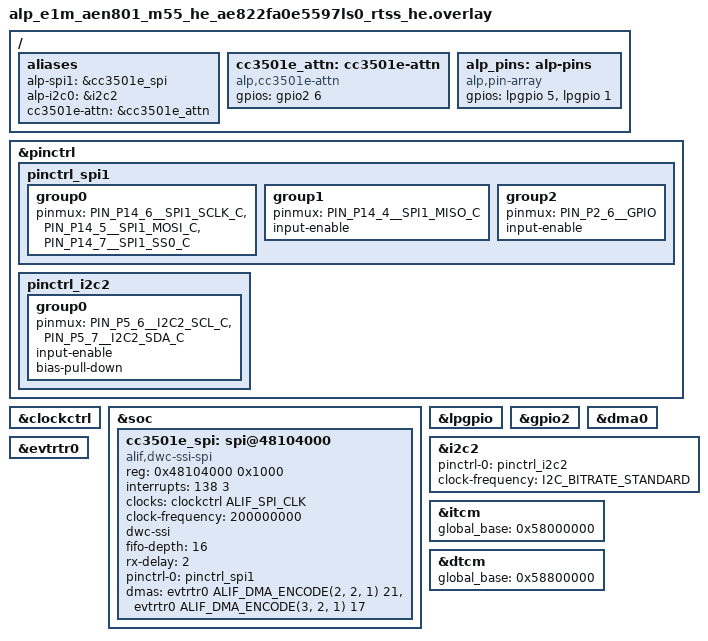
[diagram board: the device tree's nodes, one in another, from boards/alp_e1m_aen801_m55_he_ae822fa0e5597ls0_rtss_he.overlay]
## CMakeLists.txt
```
# SPDX-License-Identifier: Apache-2.0

cmake_minimum_required(VERSION 3.20)

if(DEFINED ENV{ALP_SDK_ROOT})
    set(ALP_SDK_ROOT $ENV{ALP_SDK_ROOT})
else()
    get_filename_component(ALP_SDK_ROOT ${CMAKE_CURRENT_SOURCE_DIR}/../../.. ABSOLUTE)
endif()

find_package(Zephyr REQUIRED HINTS $ENV{ZEPHYR_BASE})
project(aen_cc3501e_bringup LANGUAGES C)

target_sources(app PRIVATE src/main.c)
# Reusable SoM bring-up helper (cc3501e_bridge_bringup): the one-call CC3501E bridge
# init the example + applications use. Copyable template -- see cc3501e_bridge.h.
target_sources(app PRIVATE src/cc3501e_bridge.c)
# E1M-AEN GPIO-proxy route table: strong override of the WEAK
# cc3501e_gpio_routes[] in src/backends/gpio/cc3501e_proxy_routes_weak.c
# (E1M IO pin_id -> raw CC3501E GPIO). Auto-generated by
# scripts/gen_cc3501e_gpio_routes.py -- do not edit by hand, regenerate.
# Built unconditionally; only consulted when CONFIG_ALP_SDK_GPIO_CC3501E_PROXY
# is enabled (prj.conf).
target_sources(app PRIVATE src/cc3501e_gpio_routes.c)

# Opt-in OTA streaming demo (Step 7.5 in main.c). Left OFF by default so a
# normal bring-up run never kicks a (disruptive) flash cycle.
#   -DCC3501E_OTA_DEMO=ON  -- stream an inert blob (proves the wire path only).
#   -DCC3501E_OTA_REAL=ON  -- stream the genuine signed candidate image
#                             (v0.0.4.0), so FINISH reaches a real STAGED. This
#                             compiles the shared candidate blob from firmware/
#                             so the extern resolves; it implies OTA_DEMO.
#   -DCC3501E_OTA_PROMOTE=ON -- do not stream; PROMOTE an image a prior OTA_REAL
#                             run left STAGED. It runs in a later boot, so the
#                             device refuses (OTA_STATUS reserved[0] = 119) and
#                             the image stays STAGED (#2741): this mode shows
#                             the refusal, it cannot swap. Implies OTA_DEMO.
option(CC3501E_OTA_DEMO "Enable the opt-in CC3501E OTA streaming demo" OFF)
option(CC3501E_OTA_REAL "OTA demo streams the real signed candidate image" OFF)
option(CC3501E_OTA_PROMOTE "OTA demo shows that a PROMOTE in a later boot is refused" OFF)
if(CC3501E_OTA_DEMO OR CC3501E_OTA_REAL OR CC3501E_OTA_PROMOTE)
    target_compile_definitions(app PRIVATE CC3501E_OTA_DEMO)
endif()
if(CC3501E_OTA_REAL)
    target_compile_definitions(app PRIVATE CC3501E_OTA_REAL)
    target_sources(app PRIVATE
        ${ALP_SDK_ROOT}/cc3501e-bridge-firmware:hal/ti/cc3501e_ota_candidate.c)
endif()
if(CC3501E_OTA_PROMOTE)
    target_compile_definitions(app PRIVATE CC3501E_OTA_PROMOTE)
endif()
```

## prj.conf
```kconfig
# SPDX-License-Identifier: Apache-2.0
#
# CONFIG_SPI / CONFIG_GPIO are pulled in from board.yaml's `peripherals:`
# block (via the generated alp.conf); this file carries only the console.
CONFIG_PRINTK=y
CONFIG_LOG=y

# The reset sequence + soak use busy/sleep waits; a generous main-thread
# stack keeps the (modest) driver scratch buffers comfortable.
CONFIG_MAIN_STACK_SIZE=32768

# Link the app at the HE MRAM app partition (0x80010000) so its vector table
# matches the ATOC load address (app-zephyr-he.json mramAddress=0x80010000).
# FLASH_BASE is the full MRAM (0x80000000); without this 0x10000 offset the
# image links at 0x80000000 and the SES boots it 64 KB low -> fault/no-boot.
# (Bench recovery 2026-06-16 after a --pristine rebuild reset FLASH_LOAD_OFFSET.)
CONFIG_FLASH_LOAD_OFFSET=0x10000

# Route the proxied E1M IOs (cc3501e_gpio_routes[] in src/cc3501e_gpio_routes.c)
# through the CC3501E bridge: alp_gpio_open(ALP_E1M_GPIO_IOxx) for a mapped IO goes over
# the inter-chip link; the Alif's own pins delegate to the platform GPIO driver.
CONFIG_ALP_SDK_GPIO_CC3501E_PROXY=y

# Host-side peripheral DMA for continuous SPI streams (CC3501E bridge).
# Vendored peripheral-flow PL330 + event-router mux + the spi_dw_alif DMA path.
CONFIG_DMA=y
CONFIG_DMA_PL330_ALIF=y
CONFIG_DMA_ALIF_EVENT_ROUTER=y
CONFIG_SPI_DW_ALIF_USE_DMA=y
# KEEP THIS ABOVE THE BRIDGE FRAME SIZE.  Silicon-measured 2026-08-23 on
# an AEN EVK bench unit: at 64 the 512-byte CC3501E request-payload phase took the DMA
# path and cost 15723 us against 286 us of wire time at ~14.3 MHz -- 55x -- and
# then FAILED, so 2156 of 2157 OTA_WRITEs lost their reply and had to be
# recovered by polling OTA_STATUS to discover the chunk had landed anyway.  The
# 4-byte header phases stayed on PIO and cost 15 us, which is what made the
# DMA path identifiable at all.
#
# Above the frame size every phase is PIO: the payload phase drops to 256 us
# (i.e. wire speed), 2156 of 2157 writes ack cleanly, and a full 1095276 B OTA
# goes from 101 s to 8 s -- ~10.8 kB/s to ~137 kB/s.
#
# The underlying spi_dw DMA defect is NOT fixed by this; it is avoided.  Anything
# that raises ALP_CC3501E_MAX_PAYLOAD must raise this too.
# KEEP THIS ABOVE THE BRIDGE FRAME SIZE -- every phase stays on PIO.
#
# Two genuine DMA defects were found and FIXED while chasing throughput (an odd
# transfer length collapsed the burst to 1, i.e. one DMA transaction per BYTE;
# and every transfer rebuilt the PL330 microcode instead of reloading the
# existing descriptor).  With both fixed DMA went 113 kB/s -> 702 kB/s and
# actually BEAT PIO's 657-678 kB/s on socket traffic.
#
# It still stays off, because OTA breaks on it.  Silicon-measured 2026-08-24:
# with payloads on DMA, OTA_WRITE returns -5 and the device latches ERROR at
# off=2044 (`OTA -> -5 ... signed image did NOT stage`); with every phase on PIO
# the same build streams the full 1095276 B image -- `OTA all 1095276 B accepted
# -- FINISH`, `OTA finish -> 0`, 8133 ms.  So a THIRD DMA problem remains,
# specific to the OTA path, and it is not worth 7% of socket throughput.
#
# A size threshold cannot split the two AT TODAY'S SIZES -- but not for the
# reason this comment used to give, and the difference matters to anyone
# re-deriving the decision.
#
# It used to read: "socket replies are ~1732 B and OTA writes are 2044 B, so
# keeping OTA on PIO while socket takes DMA would need a threshold both <=1732
# and >2044".  Those figures are from when ALP_CC3501E_MAX_PAYLOAD was 2048.
# It is 4096 now and both moved with it:
#   socket reply: want_max = MAX_PAYLOAD - CC3501E_SOCK_RECV_RESP_HDR - 1
#                 = 4096 - 24 - 1 = 4071 data bytes, ~4095 B on the wire
#   OTA write:    the CALLER picks the chunk; aen-cc3501e-bringup picks the max,
#                 ALP_CC3501E_OTA_MAX_CHUNK = MAX_PAYLOAD - 4 = 4092, ~4096 B
# So they are ~4095 vs ~4096 -- effectively identical, not 1732 vs 2044.
#
# That also shows the way out, because the two sizes are NOT equally fixed.
# The socket reply size is bounded by MAX_PAYLOAD and wants to be large; the
# OTA chunk is only capped by MAX_CHUNK and is free to shrink.  Silicon-measured
# 2026-08-26 with the OTA chunk at 1024 (~1028 B on the wire) and this threshold
# at 2048, so socket replies take DMA and every OTA write stays on PIO:
#
#   socket throughput  782205 B/s -> 858514 B/s   (+9.8%, 3 samples each)
#   full 1095900 B OTA 8.1 s      -> 16.1 s       (2.0x slower)
#   link health        ping_fail=0 both ways
#   #1123 staged FINISH-then-ABORT proof: still PASS on the DMA build
#
# The OTA path is byte-for-byte unchanged there -- its writes never reach the
# threshold -- which is why the #1123 proof still passes.  No driver change, no
# public API change, no per-transfer flag: one caller-side constant and this
# value.
#
# NOT taken, deliberately: doubling update time to gain ~10% on socket streams
# is a per-deployment judgement, not an engineering one.  Both numbers are
# recorded so it can be decided rather than re-measured.  See #1677.
#
# #1818 investigation, 2026-09-02 (root cause NOT established -- do not lower
# this on the strength of what follows without a fresh bench run):
#
# The DMASTP src_id/dst_id operand fix (dma_pl330_alif.c, this issue) is real
# but was PROVEN behaviour-neutral on silicon -- see that file's comment and
# #1818's own bench log.
#
# Re-reading the PL330 microcode generator and the DW_SSI/event-router wiring
# for a SECOND defect found that spi_dw_dma_setup_tx_channel() wrote DMATDLR
# from the UNREDUCED half-FIFO default while separately computing a possibly
# SMALLER burst_length for the PL330 dma_cfg -- disagreeing for a dummy-TX
# chunk (reached when a supplied tx_buf_set's current buffer has
# `buf == NULL`, or its buffers are exhausted while RX continues -- never for
# an RX-only transfer, which does not call this function at all) or for a
# chunk that does not divide the default burst evenly, which
# ALP_CC3501E_OTA_MAX_CHUNK (4092) is: 4092 % 8 != 0.  A first pass made the
# two match by writing burst_length into DMATDLR instead; that was REVERTED
# on review, because DMATDLR is a LOW WATERMARK, not a burst count -- it
# asserts dma_tx_req once the TX FIFO holds <= DMATDLR entries, and the only
# hardware constraint is DMATDLR + burst <= fifo_depth.  With fifo_depth=16
# (zephyr/dts/alif/ensemble_e8_peripherals.dtsi) the existing DMATDLR=8 with
# burst<=8 already satisfied that; moving DMATDLR to 4 (the OTA tail) or 1
# (a dummy-TX chunk) instead makes the PL330 refill in much smaller
# increments against a DW_apb_ssi master that gates SCLK on TX underrun --
# an unproven, potentially-regressive behavioural change with no bench
# evidence either way, so it was not made.  DMATDLR now stays the unreduced
# default (see spi_dw_alif.c, spi_dw_alif_dma_burst.h); the extracted,
# host-tested burst-length calculation the #1818 pass left behind is kept --
# it only feeds the PL330 dma_cfg, which does need to match the actual
# burst, unlike DMATDLR.
#
# Also corrected in that pass: ALP_CC3501E_OTA_MAX_CHUNK (4092) never itself
# reaches spi_dw_dma_setup_tx_channel() as a chunk -- the bulk/tail split in
# spi_dw_dma_transceive() (zephyr/drivers/spi/spi_dw_alif.c) aligns it down
# to a 4088 B bulk chunk first, leaving a separate 4-item tail chunk.
#
# A second candidate was examined and NOT acted on: cc3501e_t's rx_scratch/
# tx_scratch/*_scan_buf/sock_buf fields (include/alp/chips/cc3501e/core.h) are
# plain adjacent uint8_t arrays with no cache-line alignment or padding, and
# Zephyr's sys_cache_data_invd_range() contract is explicit that a
# partially-covered line is invalidated in full (also written down at
# include/alp/peripheral.h's "DMA and the data cache" section, added by
# #1830).  That is a latent hazard once DMA is used below
# ALP_CC3501E_MAX_PAYLOAD (4096) -- currently never, since MIN_LEN stays above
# it -- but socket traffic reportedly reached 702 kB/s over DMA through this
# exact rx_scratch buffer via the identical cc3501e_request_locked() code
# path, which argues against it being what selectively breaks OTA_WRITE.  Not
# fixed here: no struct-layout/offset evidence was gathered (would need a
# compiled build, not available in this investigation), and restructuring a
# public driver context's buffer layout on that strength would be a guess.
#
# At this MIN_LEN (8192), DMA is not merely gating OTA_WRITE: the CC3501E's
# largest single transceive is ALP_CC3501E_MAX_PAYLOAD = 4096
# (include/alp/protocol/cc3501e.h), always below 8192, so DMA is disabled for
# EVERY CC3501E SPI transfer this example makes, not just OTA writes.
#
# What is still unknown: a concrete, silicon-observed explanation for why the
# bridge's actual OTA_WRITE traffic -- not a synthetic round-size probe --
# either times out or corrupts data on the DMA TX path below this threshold.
# See #1818 for history; the next bench step is a register dump of
# DBGSTATUS/FSRC/CS0 and a scope trace of DMA_TX_REQ/DMA_TX_ACK on a real,
# non-power-of-two OTA_WRITE chunk.
#
# Also open, and not resolvable from source reading alone:
# spi_dw_dma_enable_channels() (zephyr/drivers/spi/spi_dw_alif.c) clears
# SSIENR, writes DMACR, then sets SSIENR again before returning -- so every
# write_dmatdlr() / write_dmardlr() call in spi_dw_dma_setup_tx_channel() /
# _rx_channel() executes with the controller already enabled.  Whether the
# DW_apb_ssi honours a watermark-register write in that state is unverified;
# one bench read-back via the driver's existing read_dmatdlr()/read_dmardlr()
# helpers, immediately after the write, would settle it.  Do not assume
# either answer.
CONFIG_SPI_DW_ALIF_DMA_MIN_LEN=8192

# perf(#1677): pack 2 bytes per FIFO slot on the polled bulk phases.  The DR
# shifts MSB-first, so writing the stream's next bytes big-endian into a
# 16-bit frame puts exactly the same bits on the wire as two 8-bit frames --
# the peer cannot tell.  What it buys is MMIO accesses, which are what the
# polled loop actually costs: measured 912 -> 1139 KB/s on an AEN EVK bench unit.
CONFIG_SPI_DW_ALIF_PACK32=y
```

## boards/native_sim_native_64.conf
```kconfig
# SPDX-License-Identifier: Apache-2.0
#
# native_sim has no real SPI controller; pull in the emul SPI driver so
# the alp-spi1 bus enumerates at boot.  Auto-loaded by Zephyr when
# building for native_sim/native/64.  (On the real AEN board the alp-spi1
# alias resolves to the dwc-ssi SPI1 controller instead -- see
# boards/alp_e1m_aen801_m55_he.overlay.)

CONFIG_EMUL=y
CONFIG_SPI_EMUL=y
```

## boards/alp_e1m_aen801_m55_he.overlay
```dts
/*
 * Copyright (c) 2026 Alp Lab AB
 * SPDX-License-Identifier: Apache-2.0
 *
 * Inter-chip wiring for the CC3501E bring-up on the E1M-AEN801 (Alif
 * Ensemble E8, M55-HE).  Declares the SoM-internal Alif<->CC3501E link:
 * the SPI1 master bus + the two host-driven control nets, all from
 * metadata/e1m_modules/aen/inter-chip.tsv:
 *
 *   SPI1.SCK  P14_6   SPI1.MOSI P14_5   SPI1.MISO P14_4   (-> CC3501E GPIO_27/28/29)
 *   WIFI_EN   P15_5 (lpgpio 5)          E_WIFI.NRST P15_1_FLEX (lpgpio 1)
 *
 * "P15" is the Alif low-power GPIO island (lpgpio @ 0x42002000); the
 * _FLEX pads are its pins.  P14 is a main-domain port used here purely as
 * the SPI1 function via pinctrl, so no gpio14 controller node is needed.
 *
 * BENCH-UNVERIFIED.  Like the rest of the alp-sdk Alif peripheral layer
 * (zephyr/dts/alif/ensemble_e8_peripherals.dtsi), the addresses/IRQs are
 * transcribed from the Apache-2.0 alifsemi/zephyr_alif fork + the AE822
 * TRM and have NOT been validated on silicon.  The single hard BENCH-TBD
 * is the SPI1 pinctrl alt-function suffix (see the pinctrl group) -- if a
 * macro name is wrong the build fails loudly, which is the intended
 * forcing function to confirm it against the TRM pin-mux table.
 */

#include <zephyr/dt-bindings/pinctrl/alif-ensemble-pinctrl.h>
#include <zephyr/dt-bindings/gpio/gpio.h>

&pinctrl {
	/*
	 * SPI1 master on P14_6 (SCK) / P14_5 (MOSI) / P14_4 (MISO).
	 *
	 * BENCH-TBD: the alt-function suffix on each PIN_P14_x__SPI1_* macro is
	 * unconfirmed -- the Alif pinctrl header may name these *_A/_B/_C/_D
	 * (as it does for UART5_RX_A / I2C2_SCL_C elsewhere on this SoM).
	 * Confirm the exact macro names against
	 * zephyr/dt-bindings/pinctrl/alif-ensemble-pinctrl.h and the AE822 TRM
	 * pin-mux table before the first flash; a wrong name is a build error,
	 * not a silent mis-route.
	 *
	 * input-enable on MISO so the pad can sense the slave's drive (the same
	 * read-enable requirement the I2C pads need on this SoC).
	 */
	pinctrl_spi1: pinctrl_spi1 {
		group0 {
			pinmux = <PIN_P14_6__SPI1_SCLK>, <PIN_P14_5__SPI1_MOSI>;
		};
		group1 {
			pinmux = <PIN_P14_4__SPI1_MISO>;
			input-enable;
		};
	};
};

/*
 * DWC_ssi SPI1 (AHB) -- the on-SoM CC3501E inter-chip link.  Deliberately
 * NOT in ensemble_e8_peripherals.dtsi (that dtsi declares only the
 * customer-facing edge SPI0); this is the SoM-internal Wi-Fi link, so it
 * lives in the consuming app's overlay.  Same driver + flags as spi0
 * (compatible "alif,dwc-ssi-spi", dwc-ssi layout, fifo-depth 16,
 * frequency-only ALIF_SPI_CLK).
 *
 * reg 0x48104000 = SPI1 base (spi0 is 0x48103000, +0x1000/instance).
 * BENCH-TBD: interrupts = <138 3> follows the consecutive pattern from
 * spi0's IRQ 137 -- confirm SPI1_IRQ against the fork's e1.dtsi / TRM.
 *
 * No cs-gpios / HW-SS: this rev runs CS-less 3-wire (the host driver
 * clocks fixed-count lockstep transfers; see chips/cc3501e/cc3501e.c).
 */
&clockctrl {
	status = "okay";
};

&soc {
	cc3501e_spi: spi@48104000 {
		compatible = "alif,dwc-ssi-spi";
		#address-cells = <1>;
		#size-cells = <0>;
		reg = <0x48104000 0x1000>;
		interrupts = <138 3>;          /* BENCH-TBD: confirm SPI1 IRQ */
		clocks = <&clockctrl ALIF_SPI_CLK>;
		dwc-ssi;
		fifo-depth = <16>;
		pinctrl-0 = <&pinctrl_spi1>;
		pinctrl-names = "default";
		status = "okay";
	};
};

/*
 * Enable the LP GPIO island so WIFI_EN (P15_5) and E_WIFI.NRST
 * (P15_1_FLEX) are drivable as outputs.  gpio_dw needs no clocks/pinctrl
 * on the controller; the pad->GPIO function for the FLEX pins is the
 * lpgpio default.  (BENCH-TBD: if a FLEX pad comes up muxed to an LP
 * peripheral instead of GPIO, add a pinctrl group selecting its GPIO
 * function.)
 */
&lpgpio {
	status = "okay";
};

/ {
	aliases {
		/* bus_id 1 in alp_spi_open() -> this controller. */
		alp-spi1 = &cc3501e_spi;
	};

	/*
	 * Compact 2-entry control array for the SoM-internal CC3501E nets, in
	 * the order the app's CC3501E_PIN_* indices expect.  These are NOT E1M
	 * edge pads, so this bring-up app intentionally does NOT use the
	 * 52-slot positional E1M map; a production board file appends such
	 * SoM-internal control nets after the E1M pad slots.
	 */
	alp_pins: alp-pins {
		compatible = "alp,pin-array";
		gpios = <&lpgpio 5 GPIO_ACTIVE_HIGH>,   /* [0] WIFI_EN     (P15_5)      */
			<&lpgpio 1 GPIO_ACTIVE_HIGH>;   /* [1] E_WIFI.NRST (P15_1_FLEX) */
	};
};
```

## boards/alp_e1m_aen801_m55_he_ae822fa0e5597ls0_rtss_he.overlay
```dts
/*
 * Copyright (c) 2026 Alp Lab AB
 * SPDX-License-Identifier: Apache-2.0
 *
 * Inter-chip wiring for the CC3501E bring-up on the E1M-AEN801 (Alif
 * Ensemble E8, M55-HE).  Declares the SoM-internal Alif<->CC3501E link:
 * the SPI1 master bus + the two host-driven control nets, all from
 * metadata/e1m_modules/aen/inter-chip.tsv:
 *
 *   SPI1.SCK  P14_6   SPI1.MOSI P14_5   SPI1.MISO P14_4   (-> CC3501E GPIO_27/28/29)
 *   WIFI_EN   P15_5 (lpgpio 5)          E_WIFI.NRST P15_1_FLEX (lpgpio 1)
 *
 * "P15" is the Alif low-power GPIO island (lpgpio @ 0x42002000); the
 * _FLEX pads are its pins.  P14 is a main-domain port used here purely as
 * the SPI1 function via pinctrl, so no gpio14 controller node is needed.
 *
 * BENCH-UNVERIFIED.  Like the rest of the alp-sdk Alif peripheral layer
 * (zephyr/dts/alif/ensemble_e8_peripherals.dtsi), the addresses/IRQs are
 * transcribed from the Apache-2.0 alifsemi/zephyr_alif fork + the AE822
 * TRM and have NOT been validated on silicon.  The SPI1 pinctrl macros are
 * RESOLVED against zephyr/dt-bindings/pinctrl/alif-ensemble-pinctrl.h
 * (SPI1 on P14_4/5/6 = alt-2, the `_C` suffix) and the LP-GPIO mux is the
 * reset default (alt-0 = LPGPIO); the one remaining genuine unknown is the
 * SPI1 IRQ number (upstream Zephyr declares no SPI node, so it is not in
 * the build tree) -- confirm it against the AE822 TRM before relying on
 * the interrupt-driven path on silicon.
 *
 * Also enables i2c2 (P5_6 SCL_C / P5_7 SDA_C) + the `alp-i2c0` alias -- the
 * on-module EEPROM manifest bus alp_hw_info_read() opens as bus_id 0.
 * Without it the manifest read structurally cannot succeed and the banner
 * falls back to the raw board target instead of the SoM identity; see #1870.
 * Same pinctrl (input-enable + bias-pull-down) as
 * examples/peripheral-io/alp-console's bench-validated overlay -- do NOT
 * "correct" the pull direction.
 */

#include <zephyr/dt-bindings/pinctrl/alif-ensemble-pinctrl.h>
#include <zephyr/dt-bindings/gpio/gpio.h>
#include <zephyr/dt-bindings/dma/alif_dma_event_router.h>
#include <zephyr/dt-bindings/i2c/i2c.h>

&pinctrl {
	/*
	 * SPI1 master on P14_6 (SCK) / P14_5 (MOSI) / P14_4 (MISO).
	 *
	 * RESOLVED against alif-ensemble-pinctrl.h: the SPI1 functions on these
	 * three pads are alt-2, named with the `_C` suffix
	 * (PIN_P14_6__SPI1_SCLK_C = ALIF_PINMUX(14, 6, 2), etc.).  input-enable
	 * on MISO so the pad can sense the slave's drive (the same read-enable
	 * requirement the I2C pads need on this SoC).
	 */
	pinctrl_spi1: pinctrl_spi1 {
		group0 {
			/* Hardware SS0 chip-select (P14_7 = SPI1_SS0_C) -- dwc-ssi master
			 * drives SS0 per transfer to frame the CC3501E slave. */
			pinmux = <PIN_P14_6__SPI1_SCLK_C>, <PIN_P14_5__SPI1_MOSI_C>,
				 <PIN_P14_7__SPI1_SS0_C>;
		};
		group1 {
			pinmux = <PIN_P14_4__SPI1_MISO_C>;
			input-enable;
		};

		/*
		 * P2_6 (E1M AH7 / I2S1_SCLK) is muxed as a plain GPIO input here -- but NOT for
		 * the cc3501e_reply_gate() READY use (cc3501e_bridge.c does not wire
		 * fw->ready_pin: on the R2 module this bench currently holds, P2_6
		 * is E1M pad AH7 / I2S1_SCLK, the EVK's Arduino CK_RST net, NOT CC35's
		 * GPIO17 READY -- see cc3501e_reply_gate()'s own doc comment in
		 * chips/cc3501e/cc3501e_core.c). This group exists ONLY for the
		 * alp,cc3501e-attn node below, which reads the same pad directly for
		 * the async-event attention edge (#1721/#130) -- a separate mechanism
		 * from the reply-gate.
		 *
		 * REVISION CAVEAT: the "clean 1.767 V line idling HIGH with narrow LOW
		 * pulses" once measured here (scope 2026-08-24) was on a separately
		 * hand-reworked r1 unit (its own serial was never recorded -- see
		 * changelog.d/1799.md) where GPIO17 really was bodge-wired to P2_6 --
		 * not evidence for the R2 module. On a standard R2 module this pad is
		 * not connected to the CC3501E at all, so the attn node below will
		 * simply never fire; it costs nothing to leave enabled.
		 *
		 * On Alif the pad INPUT BUFFER is a PADCTRL bit that only pinctrl sets
		 * -- gpio_dw drives direction in the controller and never touches the
		 * pad, and snps,designware-gpio has no pinctrl-0 property of its own --
		 * so without this group alp_gpio_read(P2_6) would read 0 forever
		 * regardless of what (if anything) drives it. It lives HERE rather than
		 * in a standalone state applied at runtime because P2_6's alternate
		 * function is SPI1_SCLK_A: a second pinctrl pass after SPI1 is up
		 * killed the bridge on silicon. In the SPI driver's single init pass it
		 * is inert.
		 */
		group2 {
			pinmux = <PIN_P2_6__GPIO>;
			input-enable;
		};
	};

	/* I2C2 master (EEPROM manifest bus): SCL P5_6 / SDA P5_7 (_C).  Same
	 * pad config as alp-console's bench-validated overlay -- input-enable
	 * for ACK-detect, bias-pull-down (the pad DSC value Alif's reference
	 * uses; the bus is pulled up on the carrier via R95/R96). */
	pinctrl_i2c2: pinctrl_i2c2 {
		group0 {
			pinmux = <PIN_P5_6__I2C2_SCL_C>, <PIN_P5_7__I2C2_SDA_C>;
			input-enable;
			bias-pull-down;
		};
	};
};

/*
 * DWC_ssi SPI1 (AHB) -- the on-SoM CC3501E inter-chip link.  Deliberately
 * NOT in ensemble_e8_peripherals.dtsi (that dtsi declares only the
 * customer-facing edge SPI0); this is the SoM-internal Wi-Fi link, so it
 * lives in the consuming app's overlay.  Same driver + flags as spi0
 * (compatible "alif,dwc-ssi-spi", dwc-ssi layout, fifo-depth 16,
 * frequency-only ALIF_SPI_CLK).
 *
 * reg 0x48104000 = SPI1 base (spi0 is 0x48103000, +0x1000/instance).
 * BENCH-TBD: interrupts = <138 3> follows the consecutive pattern from
 * spi0's IRQ 137 -- confirm SPI1_IRQ against the fork's e1.dtsi / TRM.
 *
 * No cs-gpios: P14_7 is muxed as SPI1_SS0_C above and the dwc-ssi peripheral
 * drives hardware SS0 per transfer.  The host opens ALP_SPI_NO_CS so no GPIO CS
 * is installed, allowing the SPI driver to use its hardware slave-select path.
 */
&clockctrl {
	status = "okay";
};

&soc {
	cc3501e_spi: spi@48104000 {
		compatible = "alif,dwc-ssi-spi";
		#address-cells = <1>;
		#size-cells = <0>;
		reg = <0x48104000 0x1000>;
		interrupts = <138 3>;          /* BENCH-TBD: confirm SPI1 IRQ */
		clocks = <&clockctrl ALIF_SPI_CLK>;
		/*
		 * ROOT-CAUSE FIX 2026-06-16: spi_dw_alif's configure takes the
		 * clock-control path when no clock-frequency is set, and that path
		 * fails (-EINVAL) for the gateless dummy ALIF_SPI_CLK -> every
		 * transceive returned ALP_ERR_INVAL with zero SCLK (witness fail_step=1,
		 * zerr=-EINVAL). Providing the SSI input clock here makes the driver
		 * use it directly and skip the failing clock-control path. The SSI
		 * functional clock is 200 MHz (E8 HWRM); BAUDR = clk/freq_hz.
		 */
		clock-frequency = <200000000>; /* real SSI functional clock (was mis-set 400M; proven via BAUDR scaling) */
		dwc-ssi;
		fifo-depth = <16>;
		/* MISO capture delay in SSI clocks -- INERT here, and NOT what the link
		 * runs at.  spi_dw_alif.c writes RX_SAMPLE_DLY (0xf0) from this property
		 * at init and at PM resume only; spi_dw_configure never touches the
		 * register, so src/cc3501e_bridge.c's poke right after alp_spi_open()
		 * overwrites this value with CC3501E_BRIDGE_RX_SAMPLE_DLY.
		 *
		 * It is kept because that poke is guarded on the constant being non-zero:
		 * set the constant to 0 and this property is what survives.
		 *
		 * The earlier claim here -- that 0 "fails outright" and 4 "fails too" --
		 * is contradicted by the N = 0..10 sweep on E1M-AEN803 serial
		 * 2026W36-0002 at 25 MHz: 0 and 4 each passed 3 runs of 3, and 8 is the
		 * value that hard-fails.  Sweep the constant, not this property; the
		 * measurements are recorded in src/cc3501e_bridge.h. */
		rx-delay = <2>;
		pinctrl-0 = <&pinctrl_spi1>;
		pinctrl-names = "default";
		status = "okay";
	};
};

/*
 * Enable the LP GPIO island so WIFI_EN (P15_5) and E_WIFI.NRST
 * (P15_1_FLEX) are drivable as outputs.  gpio_dw needs no clocks/pinctrl
 * on the controller, and the pad->GPIO mux needs no pinctrl group either:
 * RESOLVED against alif-ensemble-pinctrl.h -- P15_1/P15_5 function 0 (the
 * reset default) IS LPGPIO (PIN_P15_x__LPGPIO = ALIF_PINMUX(15, x, 0)).
 */
&lpgpio {
	status = "okay";
};

/*
 * gpio2 (P2_6) for the alp,cc3501e-attn async-event node below -- NOT the
 * cc3501e_reply_gate() READY input: P2_6 is not CC35 GPIO17 on this R2
 * module (see the pinctrl_spi1 group2 comment above). P2_6's reset-default
 * mux IS function 0 = GPIO (PIN_P2_6__GPIO), but the pad still needs an
 * input-enable group to turn its INPUT BUFFER on -- that lives in
 * pinctrl_spi1 group2 above. gpio_dw defaults the pin to input. */
&gpio2 {
	status = "okay";
};

/*
 * Host-side peripheral DMA for continuous SPI streams over the CC3501E bridge.
 * SPI1 is a MAIN-domain peripheral, so per the AE822 DFP soc_dma_map (SPI1_DMA=0,
 * group 2, TX req 21 / RX req 17) it routes through the SYSTOP DMA0 via its event
 * router evtrtr0 (4 groups -> group 2 valid) -- NOT the M55-HE-local DMA2/evtrtr2
 * (1 group, for LP peripherals; wiring SPI1 there leaves the channel Waiting-For-
 * Peripheral forever -- SPI1's request line isn't on the HE router).  DMA0's clock
 * is SYSTOP (already on -- the app drives SPI1/GPIO in the same region); its
 * PL330 boot-manager security latch (CLKCTRL_PER_MST) is in dma_alif_boot_latch.c.
 * The fork PL330 driver statically allocates the per-channel ucode + remaps it via
 * local_to_global(), so no external `microcode` prop is needed.
 *
 * dma0 + evtrtr0 are now declared in ensemble_e8_peripherals.dtsi (disabled
 * by default, alp-sdk issue #1815); this overlay only enables them.
 */
&dma0 {
	status = "okay";
};

&evtrtr0 {
	status = "okay";
};

/*
 * Route the bridge SPI1 through evtrtr0 to DMA0.  Cell encoding
 * (ALIF_DMA_ENCODE(channel, dma_group, handshake), periph_req):
 *   TX = PL330 ch2, evtrtr group 2, handshake on, SPI1 TX periph req 21
 *   RX = PL330 ch3, evtrtr group 2, handshake on, SPI1 RX periph req 17
 * (AE822 DFP soc_dma_map.h: SPI1 group 2, TX 21 / RX 17.)
 */
&cc3501e_spi {
	dmas = <&evtrtr0 ALIF_DMA_ENCODE(2, 2, 1) 21>,
	       <&evtrtr0 ALIF_DMA_ENCODE(3, 2, 1) 17>;
	dma-names = "txdma", "rxdma";
};

&i2c2 {
	status = "okay";
	pinctrl-0 = <&pinctrl_i2c2>;
	pinctrl-names = "default";
	clock-frequency = <I2C_BITRATE_STANDARD>;   /* 100 kHz */
};

/ {
	aliases {
		/* bus_id 1 in alp_spi_open() -> this controller. */
		alp-spi1 = &cc3501e_spi;
		alp-i2c0 = &i2c2;   /* bus 0 for alp_hw_info_read() -> EEPROM manifest */

		/*
		 * Attention line for CONFIG_ALP_SDK_CC3501E_EVENT_IRQ (#130): the
		 * companion console's edge ISR schedules a GET_PENDING_EVENTS drain
		 * instead of waiting for the ~500 ms timer poll.
		 *
		 * SAME PIN &gpio2 6 (P2_6) the pinctrl group2 comment above enables --
		 * there is no `alp_pins[2]` entry for it (cc3501e_bridge.c does not
		 * wire fw->ready_pin on this R2 module; see that comment).  On a unit
		 * where this net genuinely carries CC35 GPIO17 -- a hand-reworked r1
		 * unit, not the stock R2 module -- there is one slave->master wire and
		 * it already carries READY flow control; the firmware (built with
		 * CC3501E_ATTN_PULSE) gives it an edge when an event is queued while
		 * the bridge is idle.  Draining on ANY rising edge is safe -- an empty
		 * ring answers with an empty list -- so the host never has to tell
		 * attention from an ordinary re-arm.
		 *
		 * BODGE-GATED: this net is a rev-1 wire, absent on the stock EVK,
		 * which is why CONFIG_ALP_SDK_CC3501E_EVENT_IRQ stays default-off.
		 * The alias existing does nothing on its own.
		 */
		cc3501e-attn = &cc3501e_attn;
	};

	/* Node the cc3501e-attn alias points at; `gpios` is what
	 * GPIO_DT_SPEC_GET(DT_ALIAS(cc3501e_attn), gpios) reads. */
	/* NO compatible: GPIO_DT_SPEC_GET() only needs the `gpios` phandle-array.
	 * Declaring "alp,pin-array" here made a SECOND node of that compatible and
	 * broke the SDK's pin-array resolution outright -- bridge bring-up failed
	 * with err=-1 ("SPI bus 1 / WIFI_EN+nRESET absent?") because alp_pins no
	 * longer resolved. Bench-caught 2026-08-26. */
	cc3501e_attn: cc3501e-attn {
		compatible = "alp,cc3501e-attn";
		gpios = <&gpio2 6 GPIO_ACTIVE_HIGH>;
	};

	/*
	 * Compact 2-entry control array for the SoM-internal CC3501E control
	 * nets, in the order the app's CC3501E_PIN_* indices expect.  These are
	 * NOT E1M edge pads, so this bring-up app intentionally does NOT use the
	 * 52-slot positional E1M map; a production board file appends such
	 * SoM-internal control nets after the E1M pad slots.  No READY entry
	 * here -- P2_6/&gpio2 stays enabled above only for the cc3501e-attn node,
	 * which reads it directly, not through this array. */
	alp_pins: alp-pins {
		compatible = "alp,pin-array";
		gpios = <&lpgpio 5 GPIO_ACTIVE_HIGH>, /* [0] WIFI_EN     (P15_5)      */
			<&lpgpio 1 GPIO_ACTIVE_HIGH>; /* [1] E_WIFI.NRST (P15_1_FLEX) */
	};
};

/*
 * Global-bus aliases of the M55-HE TCMs, needed by hal_alif soc_memory_map.h
 * local_to_global() -- the PL330 (AXI master) reaches TCM-resident buffers only
 * via these global windows.  Values from the AE822 M55-HE map (sdk-alif fork
 * ensemble_rtss_he.dtsi): ITCM 0x0->0x58000000, DTCM 0x20000000->0x58800000.
 * (DMA stream buffers still belong in SRAM0 0x02000000, which is already global
 * -> local_to_global() returns it unchanged.)
 */
&itcm {
	global_base = <0x58000000>;
};
&dtcm {
	global_base = <0x58800000>;
};
```

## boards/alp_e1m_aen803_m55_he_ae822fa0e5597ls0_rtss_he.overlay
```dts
/*
 * Copyright (c) 2026 Alp Lab AB
 * SPDX-License-Identifier: Apache-2.0
 *
 * Inter-chip wiring for the CC3501E bring-up on the E1M-AEN803 (Alif
 * Ensemble E8, M55-HE).  Declares the SoM-internal Alif<->CC3501E link:
 * the SPI1 master bus + the two host-driven control nets, all from
 * metadata/e1m_modules/aen/inter-chip.tsv:
 *
 *   SPI1.SCK  P14_6   SPI1.MOSI P14_5   SPI1.MISO P14_4   (-> CC3501E GPIO_27/28/29)
 *   WIFI_EN   P15_5 (lpgpio 5)          E_WIFI.NRST P15_1_FLEX (lpgpio 1)
 *
 * "P15" is the Alif low-power GPIO island (lpgpio @ 0x42002000); the
 * _FLEX pads are its pins.  P14 is a main-domain port used here purely as
 * the SPI1 function via pinctrl, so no gpio14 controller node is needed.
 *
 * BENCH-UNVERIFIED.  Like the rest of the alp-sdk Alif peripheral layer
 * (zephyr/dts/alif/ensemble_e8_peripherals.dtsi), the addresses/IRQs are
 * transcribed from the Apache-2.0 alifsemi/zephyr_alif fork + the AE822
 * TRM and have NOT been validated on silicon.  The SPI1 pinctrl macros are
 * RESOLVED against zephyr/dt-bindings/pinctrl/alif-ensemble-pinctrl.h
 * (SPI1 on P14_4/5/6 = alt-2, the `_C` suffix) and the LP-GPIO mux is the
 * reset default (alt-0 = LPGPIO); the one remaining genuine unknown is the
 * SPI1 IRQ number (upstream Zephyr declares no SPI node, so it is not in
 * the build tree) -- confirm it against the AE822 TRM before relying on
 * the interrupt-driven path on silicon.
 *
 * Also enables i2c2 (P5_6 SCL_C / P5_7 SDA_C) + the `alp-i2c0` alias -- the
 * on-module EEPROM manifest bus alp_hw_info_read() opens as bus_id 0.
 * Without it the manifest read structurally cannot succeed and the banner
 * falls back to the raw board target instead of the SoM identity; see #1870.
 * Same pinctrl (input-enable + bias-pull-down) as
 * examples/peripheral-io/alp-console's bench-validated overlay -- do NOT
 * "correct" the pull direction.
 */

#include <zephyr/dt-bindings/pinctrl/alif-ensemble-pinctrl.h>
#include <zephyr/dt-bindings/gpio/gpio.h>
#include <zephyr/dt-bindings/dma/alif_dma_event_router.h>
#include <zephyr/dt-bindings/i2c/i2c.h>

&pinctrl {
	/*
	 * SPI1 master on P14_6 (SCK) / P14_5 (MOSI) / P14_4 (MISO).
	 *
	 * RESOLVED against alif-ensemble-pinctrl.h: the SPI1 functions on these
	 * three pads are alt-2, named with the `_C` suffix
	 * (PIN_P14_6__SPI1_SCLK_C = ALIF_PINMUX(14, 6, 2), etc.).  input-enable
	 * on MISO so the pad can sense the slave's drive (the same read-enable
	 * requirement the I2C pads need on this SoC).
	 */
	pinctrl_spi1: pinctrl_spi1 {
		group0 {
			/* Hardware SS0 chip-select (P14_7 = SPI1_SS0_C) -- dwc-ssi master
			 * drives SS0 per transfer to frame the CC3501E slave. */
			pinmux = <PIN_P14_6__SPI1_SCLK_C>, <PIN_P14_5__SPI1_MOSI_C>,
				 <PIN_P14_7__SPI1_SS0_C>;
		};
		group1 {
			pinmux = <PIN_P14_4__SPI1_MISO_C>;
			input-enable;
		};

		/*
		 * P2_6 (E1M AH7 / I2S1_SCLK) is muxed as a plain GPIO input here -- but NOT for
		 * the cc3501e_reply_gate() READY use (cc3501e_bridge.c does not wire
		 * fw->ready_pin: on the R2 module this bench currently holds, P2_6
		 * is E1M pad AH7 / I2S1_SCLK, the EVK's Arduino CK_RST net, NOT CC35's
		 * GPIO17 READY -- see cc3501e_reply_gate()'s own doc comment in
		 * chips/cc3501e/cc3501e_core.c). This group exists ONLY for the
		 * alp,cc3501e-attn node below, which reads the same pad directly for
		 * the async-event attention edge (#1721/#130) -- a separate mechanism
		 * from the reply-gate.
		 *
		 * REVISION CAVEAT: the "clean 1.767 V line idling HIGH with narrow LOW
		 * pulses" once measured here (scope 2026-08-24) was on a separately
		 * hand-reworked r1 unit (its own serial was never recorded -- see
		 * changelog.d/1799.md) where GPIO17 really was bodge-wired to P2_6 --
		 * not evidence for the R2 module. On a standard R2 module this pad is
		 * not connected to the CC3501E at all, so the attn node below will
		 * simply never fire; it costs nothing to leave enabled.
		 *
		 * On Alif the pad INPUT BUFFER is a PADCTRL bit that only pinctrl sets
		 * -- gpio_dw drives direction in the controller and never touches the
		 * pad, and snps,designware-gpio has no pinctrl-0 property of its own --
		 * so without this group alp_gpio_read(P2_6) would read 0 forever
		 * regardless of what (if anything) drives it. It lives HERE rather than
		 * in a standalone state applied at runtime because P2_6's alternate
		 * function is SPI1_SCLK_A: a second pinctrl pass after SPI1 is up
		 * killed the bridge on silicon. In the SPI driver's single init pass it
		 * is inert.
		 */
		group2 {
			pinmux = <PIN_P2_6__GPIO>;
			input-enable;
		};
	};

	/* I2C2 master (EEPROM manifest bus): SCL P5_6 / SDA P5_7 (_C).  Same
	 * pad config as alp-console's bench-validated overlay -- input-enable
	 * for ACK-detect, bias-pull-down (the pad DSC value Alif's reference
	 * uses; the bus is pulled up on the carrier via R95/R96). */
	pinctrl_i2c2: pinctrl_i2c2 {
		group0 {
			pinmux = <PIN_P5_6__I2C2_SCL_C>, <PIN_P5_7__I2C2_SDA_C>;
			input-enable;
			bias-pull-down;
		};
	};
};

/*
 * DWC_ssi SPI1 (AHB) -- the on-SoM CC3501E inter-chip link.  Deliberately
 * NOT in ensemble_e8_peripherals.dtsi (that dtsi declares only the
 * customer-facing edge SPI0); this is the SoM-internal Wi-Fi link, so it
 * lives in the consuming app's overlay.  Same driver + flags as spi0
 * (compatible "alif,dwc-ssi-spi", dwc-ssi layout, fifo-depth 16,
 * frequency-only ALIF_SPI_CLK).
 *
 * reg 0x48104000 = SPI1 base (spi0 is 0x48103000, +0x1000/instance).
 * BENCH-TBD: interrupts = <138 3> follows the consecutive pattern from
 * spi0's IRQ 137 -- confirm SPI1_IRQ against the fork's e1.dtsi / TRM.
 *
 * No cs-gpios: P14_7 is muxed as SPI1_SS0_C above and the dwc-ssi peripheral
 * drives hardware SS0 per transfer.  The host opens ALP_SPI_NO_CS so no GPIO CS
 * is installed, allowing the SPI driver to use its hardware slave-select path.
 */
&clockctrl {
	status = "okay";
};

&soc {
	cc3501e_spi: spi@48104000 {
		compatible = "alif,dwc-ssi-spi";
		#address-cells = <1>;
		#size-cells = <0>;
		reg = <0x48104000 0x1000>;
		interrupts = <138 3>;          /* BENCH-TBD: confirm SPI1 IRQ */
		clocks = <&clockctrl ALIF_SPI_CLK>;
		/*
		 * ROOT-CAUSE FIX 2026-06-16: spi_dw_alif's configure takes the
		 * clock-control path when no clock-frequency is set, and that path
		 * fails (-EINVAL) for the gateless dummy ALIF_SPI_CLK -> every
		 * transceive returned ALP_ERR_INVAL with zero SCLK (witness fail_step=1,
		 * zerr=-EINVAL). Providing the SSI input clock here makes the driver
		 * use it directly and skip the failing clock-control path. The SSI
		 * functional clock is 200 MHz (E8 HWRM); BAUDR = clk/freq_hz.
		 */
		clock-frequency = <200000000>; /* real SSI functional clock (was mis-set 400M; proven via BAUDR scaling) */
		dwc-ssi;
		fifo-depth = <16>;
		/* MISO capture delay in SSI clocks -- INERT here, and NOT what the link
		 * runs at.  spi_dw_alif.c writes RX_SAMPLE_DLY (0xf0) from this property
		 * at init and at PM resume only; spi_dw_configure never touches the
		 * register, so src/cc3501e_bridge.c's poke right after alp_spi_open()
		 * overwrites this value with CC3501E_BRIDGE_RX_SAMPLE_DLY.
		 *
		 * It is kept because that poke is guarded on the constant being non-zero:
		 * set the constant to 0 and this property is what survives.
		 *
		 * The earlier claim here -- that 0 "fails outright" and 4 "fails too" --
		 * is contradicted by the N = 0..10 sweep on E1M-AEN803 serial
		 * 2026W36-0002 at 25 MHz: 0 and 4 each passed 3 runs of 3, and 8 is the
		 * value that hard-fails.  Sweep the constant, not this property; the
		 * measurements are recorded in src/cc3501e_bridge.h. */
		rx-delay = <2>;
		pinctrl-0 = <&pinctrl_spi1>;
		pinctrl-names = "default";
		status = "okay";
	};
};

/*
 * Enable the LP GPIO island so WIFI_EN (P15_5) and E_WIFI.NRST
 * (P15_1_FLEX) are drivable as outputs.  gpio_dw needs no clocks/pinctrl
 * on the controller, and the pad->GPIO mux needs no pinctrl group either:
 * RESOLVED against alif-ensemble-pinctrl.h -- P15_1/P15_5 function 0 (the
 * reset default) IS LPGPIO (PIN_P15_x__LPGPIO = ALIF_PINMUX(15, x, 0)).
 */
&lpgpio {
	status = "okay";
};

/*
 * gpio2 (P2_6) for the alp,cc3501e-attn async-event node below -- NOT the
 * cc3501e_reply_gate() READY input: P2_6 is not CC35 GPIO17 on this R2
 * module (see the pinctrl_spi1 group2 comment above). P2_6's reset-default
 * mux IS function 0 = GPIO (PIN_P2_6__GPIO), but the pad still needs an
 * input-enable group to turn its INPUT BUFFER on -- that lives in
 * pinctrl_spi1 group2 above. gpio_dw defaults the pin to input. */
&gpio2 {
	status = "okay";
};

/*
 * Host-side peripheral DMA for continuous SPI streams over the CC3501E bridge.
 * SPI1 is a MAIN-domain peripheral, so per the AE822 DFP soc_dma_map (SPI1_DMA=0,
 * group 2, TX req 21 / RX req 17) it routes through the SYSTOP DMA0 via its event
 * router evtrtr0 (4 groups -> group 2 valid) -- NOT the M55-HE-local DMA2/evtrtr2
 * (1 group, for LP peripherals; wiring SPI1 there leaves the channel Waiting-For-
 * Peripheral forever -- SPI1's request line isn't on the HE router).  DMA0's clock
 * is SYSTOP (already on -- the app drives SPI1/GPIO in the same region); its
 * PL330 boot-manager security latch (CLKCTRL_PER_MST) is in dma_alif_boot_latch.c.
 * The fork PL330 driver statically allocates the per-channel ucode + remaps it via
 * local_to_global(), so no external `microcode` prop is needed.
 *
 * dma0 + evtrtr0 are now declared in ensemble_e8_peripherals.dtsi (disabled
 * by default, alp-sdk issue #1815); this overlay only enables them.
 */
&dma0 {
	status = "okay";
};

&evtrtr0 {
	status = "okay";
};

/*
 * Route the bridge SPI1 through evtrtr0 to DMA0.  Cell encoding
 * (ALIF_DMA_ENCODE(channel, dma_group, handshake), periph_req):
 *   TX = PL330 ch2, evtrtr group 2, handshake on, SPI1 TX periph req 21
 *   RX = PL330 ch3, evtrtr group 2, handshake on, SPI1 RX periph req 17
 * (AE822 DFP soc_dma_map.h: SPI1 group 2, TX 21 / RX 17.)
 */
&cc3501e_spi {
	dmas = <&evtrtr0 ALIF_DMA_ENCODE(2, 2, 1) 21>,
	       <&evtrtr0 ALIF_DMA_ENCODE(3, 2, 1) 17>;
	dma-names = "txdma", "rxdma";
};

&i2c2 {
	status = "okay";
	pinctrl-0 = <&pinctrl_i2c2>;
	pinctrl-names = "default";
	clock-frequency = <I2C_BITRATE_STANDARD>;   /* 100 kHz */
};

/ {
	aliases {
		/* bus_id 1 in alp_spi_open() -> this controller. */
		alp-spi1 = &cc3501e_spi;
		alp-i2c0 = &i2c2;   /* bus 0 for alp_hw_info_read() -> EEPROM manifest */

		/*
		 * Attention line for CONFIG_ALP_SDK_CC3501E_EVENT_IRQ (#130): the
		 * companion console's edge ISR schedules a GET_PENDING_EVENTS drain
		 * instead of waiting for the ~500 ms timer poll.
		 *
		 * SAME PIN &gpio2 6 (P2_6) the pinctrl group2 comment above enables --
		 * there is no `alp_pins[2]` entry for it (cc3501e_bridge.c does not
		 * wire fw->ready_pin on this R2 module; see that comment).  On a unit
		 * where this net genuinely carries CC35 GPIO17 -- a hand-reworked r1
		 * unit, not the stock R2 module -- there is one slave->master wire and
		 * it already carries READY flow control; the firmware (built with
		 * CC3501E_ATTN_PULSE) gives it an edge when an event is queued while
		 * the bridge is idle.  Draining on ANY rising edge is safe -- an empty
		 * ring answers with an empty list -- so the host never has to tell
		 * attention from an ordinary re-arm.
		 *
		 * BODGE-GATED: this net is a rev-1 wire, absent on the stock EVK,
		 * which is why CONFIG_ALP_SDK_CC3501E_EVENT_IRQ stays default-off.
		 * The alias existing does nothing on its own.
		 */
		cc3501e-attn = &cc3501e_attn;
	};

	/* Node the cc3501e-attn alias points at; `gpios` is what
	 * GPIO_DT_SPEC_GET(DT_ALIAS(cc3501e_attn), gpios) reads. */
	/* NO compatible: GPIO_DT_SPEC_GET() only needs the `gpios` phandle-array.
	 * Declaring "alp,pin-array" here made a SECOND node of that compatible and
	 * broke the SDK's pin-array resolution outright -- bridge bring-up failed
	 * with err=-1 ("SPI bus 1 / WIFI_EN+nRESET absent?") because alp_pins no
	 * longer resolved. Bench-caught 2026-08-26. */
	cc3501e_attn: cc3501e-attn {
		compatible = "alp,cc3501e-attn";
		gpios = <&gpio2 6 GPIO_ACTIVE_HIGH>;
	};

	/*
	 * Compact 2-entry control array for the SoM-internal CC3501E control
	 * nets, in the order the app's CC3501E_PIN_* indices expect.  These are
	 * NOT E1M edge pads, so this bring-up app intentionally does NOT use the
	 * 52-slot positional E1M map; a production board file appends such
	 * SoM-internal control nets after the E1M pad slots.  No READY entry
	 * here -- P2_6/&gpio2 stays enabled above only for the cc3501e-attn node,
	 * which reads it directly, not through this array. */
	alp_pins: alp-pins {
		compatible = "alp,pin-array";
		gpios = <&lpgpio 5 GPIO_ACTIVE_HIGH>, /* [0] WIFI_EN     (P15_5)      */
			<&lpgpio 1 GPIO_ACTIVE_HIGH>; /* [1] E_WIFI.NRST (P15_1_FLEX) */
	};
};

/*
 * Global-bus aliases of the M55-HE TCMs, needed by hal_alif soc_memory_map.h
 * local_to_global() -- the PL330 (AXI master) reaches TCM-resident buffers only
 * via these global windows.  Values from the AE822 M55-HE map (sdk-alif fork
 * ensemble_rtss_he.dtsi): ITCM 0x0->0x58000000, DTCM 0x20000000->0x58800000.
 * (DMA stream buffers still belong in SRAM0 0x02000000, which is already global
 * -> local_to_global() returns it unchanged.)
 */
&itcm {
	global_base = <0x58000000>;
};
&dtcm {
	global_base = <0x58800000>;
};
```

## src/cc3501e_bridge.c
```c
/*
 * SPDX-License-Identifier: Apache-2.0
 * Copyright 2026 Alp Lab AB
 *
 * E1M-AEN SoM CC3501E bridge bring-up helper -- see cc3501e_bridge.h.
 */

#include "cc3501e_bridge.h"

#if defined(CONFIG_BOARD_ALP_E1M_AEN801_M55_HE)
#include <zephyr/arch/cpu.h>
#include <zephyr/sys/sys_io.h>
/*
 * AEN LP-pad mux (Alif Ensemble E8, M55-HE).  WIFI_EN (P15_5) and nRESET (P15_1)
 * are on the Alif LP-GPIO island, bound by the generic snps,designware-gpio driver
 * which does NOT apply Alif pinctrl -- so the LP pads stay un-muxed and their output
 * drivers OFF (confirmed on silicon: WIFI_EN never powers the CC3501E until these
 * regs are set).  0x23 = the Alif GPIO-output pad config (driver + read-enable +
 * drive strength).  TODO: drop this raw poke once the Alif GPIO backend muxes the LP
 * island via pinctrl.
 */
#define ALIF_LPGPIO_PADCTRL_BASE 0x42007000u
#define ALIF_PAD_GPIO_OUTPUT     0x23u
static void aen_lp_pads_enable_output(void)
{
	sys_write32(ALIF_PAD_GPIO_OUTPUT, ALIF_LPGPIO_PADCTRL_BASE + 5u * 4u); /* P15_5 WIFI_EN */
	sys_write32(ALIF_PAD_GPIO_OUTPUT, ALIF_LPGPIO_PADCTRL_BASE + 1u * 4u); /* P15_1 nRESET  */
}
#else
static inline void aen_lp_pads_enable_output(void)
{
}
#endif

alp_status_t cc3501e_bridge_bringup(cc3501e_t *fw)
{
	if (fw == NULL) {
		return ALP_ERR_INVAL;
	}

	/* 1. Control pins: WIFI_EN (supply gate) + nRESET.  These are Alif LP-GPIO
	 *    pads, not E1M edge pads -- the SoM owns them. */
	alp_gpio_t *wifi_en = alp_gpio_open(CC3501E_BRIDGE_PIN_WIFI_EN);
	alp_gpio_t *nrst    = alp_gpio_open(CC3501E_BRIDGE_PIN_NRST);
	if (wifi_en == NULL || nrst == NULL) {
		if (wifi_en != NULL) {
			alp_gpio_close(wifi_en);
		}
		if (nrst != NULL) {
			alp_gpio_close(nrst);
		}
		return ALP_ERR_NOT_PRESENT_ON_THIS_SOC;
	}
	aen_lp_pads_enable_output();
	(void)alp_gpio_configure(wifi_en, ALP_GPIO_OUTPUT, ALP_GPIO_PULL_NONE);
	(void)alp_gpio_configure(nrst, ALP_GPIO_OUTPUT, ALP_GPIO_PULL_NONE);

	/* 2. Inter-chip SPI (Alif = master).  No chip-select this HW rev -- the link is
	 *    fixed-count lockstep (ALP_SPI_NO_CS); mode 0 matches the CC3501E vendor
	 *    image frameFormat. */
	alp_spi_t *spi = alp_spi_open(&(alp_spi_config_t){
	    .bus_id        = CC3501E_BRIDGE_SPI_BUS_ID,
	    .freq_hz       = CC3501E_BRIDGE_SPI_FREQ_HZ,
	    .mode          = ALP_SPI_MODE_0,
	    .bits_per_word = 8u,
	    .cs_pin_id     = ALP_SPI_NO_CS,
	});
	if (spi == NULL) {
		alp_gpio_close(wifi_en);
		alp_gpio_close(nrst);
		return ALP_ERR_NOT_PRESENT_ON_THIS_SOC;
	}

#if CC3501E_BRIDGE_RX_SAMPLE_DLY > 0
	/* Raise the SCLK past 1 MHz: the DW SSI RX_SAMPLE_DLY register (0xf0) delays
	 * the MISO capture point by N ssi_clk cycles to cover the on-SoM trace + crossed
	 * data round-trip.  Zephyr spi_dw never writes it (leaves 0), so without this
	 * >1 MHz mis-samples MISO (cold reqhdr_rx=0xFFFFFFFF).  Written with SSI disabled
	 * (SSIENR=0); persists across the driver's per-transfer configure.  Value is
	 * silicon-tuned -- sweep CC3501E_BRIDGE_RX_SAMPLE_DLY at the target SCLK. */
	{
		volatile uint32_t *ssienr = (volatile uint32_t *)(uintptr_t)(CC3501E_BRIDGE_SPI1_BASE + 0x08u);
		volatile uint32_t *rsd    = (volatile uint32_t *)(uintptr_t)(CC3501E_BRIDGE_SPI1_BASE + 0xf0u);
		uint32_t en = *ssienr;
		*ssienr = 0u;
		*rsd    = (uint32_t)CC3501E_BRIDGE_RX_SAMPLE_DLY;
		*ssienr = en;
	}
#endif

	/* 3. Bind the bus + control pins; attach the GPIO proxy (proxied E1M IOs then
	 *    route over the bridge); run the power + reset sequence (TI SWRU626 + the
	 *    Puya cold-boot hard-reset workaround).  Leaves WIFI_EN HIGH. */
	(void)cc3501e_init(fw, spi);
	fw->enable_pin = wifi_en;
	fw->reset_pin  = nrst;
	/* Optional host-IRQ/READY line (r2 SS0+IRQ bridge): CC35 GPIO17 -> Alif P2_6.
	 * Open + configure as input; if the board doesn't wire it (alp_pins[2] absent),
	 * alp_gpio_open returns NULL and the driver keeps the fixed-gap fallback. */
	alp_gpio_t *ready = alp_gpio_open(CC3501E_BRIDGE_PIN_READY);
	if (ready != NULL) {
		(void)alp_gpio_configure(ready, ALP_GPIO_INPUT, ALP_GPIO_PULL_NONE);
		fw->ready_pin = ready;
	}
#ifdef CONFIG_ALP_SDK_GPIO_CC3501E_PROXY
	(void)alp_gpio_cc3501e_attach(fw);
#endif
	return cc3501e_reset(fw);
}
```
